AUTOSAR XML (schema 4-3-0)
package /ComponentTypes
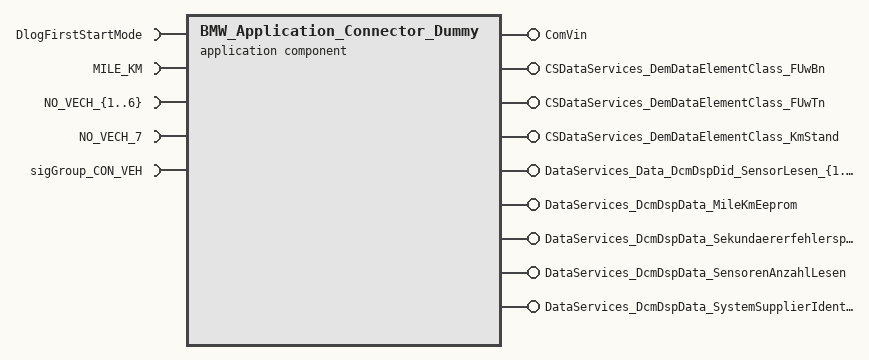
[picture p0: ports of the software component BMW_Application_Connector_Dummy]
  application sw component type BMW_Application_Connector_Dummy
    11 x provide port:
      ComVin: nonqueued-sender-com-spec{data-element=ComVin, init-value=fields=[Vin1:0, Vin2:0, Vin3:0, Vin4:0, Vin5:0, Vin6:0, Vin7:0]}, provided-interface=ComVin
      CSDataServices_DemDataElementClass_FUwBn: server-com-spec{operation=ReadData, queue-length=1}, provided-interface=CSDataServices_DemDataElementClass_FUwBn
      CSDataServices_DemDataElementClass_FUwTn: server-com-spec{operation=ReadData, queue-length=1}, provided-interface=CSDataServices_DemDataElementClass_FUwTn
      CSDataServices_DemDataElementClass_KmStand: server-com-spec{operation=ReadData, queue-length=1}, provided-interface=CSDataServices_DemDataElementClass_KmStand
      DataServices_Data_DcmDspDid_SensorLesen_{1..3}: provided-com-specs=[{operation=ConditionCheckRead, queue-length=1}, {operation=ReadData, queue-length=1}], provided-interface=DataServices_Data_DcmDspDid_SensorLesen_{1..3}
      DataServices_DcmDspData_MileKmEeprom: provided-com-specs=[{operation=ConditionCheckRead, queue-length=1}, {operation=ReadData, queue-length=1}], provided-interface=DataServices_DcmDspData_MileKmEeprom
      DataServices_DcmDspData_Sekundaererfehlerspeicher: provided-com-specs=[{operation=ConditionCheckRead, queue-length=1}, {operation=ReadData, queue-length=1}], provided-interface=DataServices_DcmDspData_Sekundaererfehlerspeicher
      DataServices_DcmDspData_SensorenAnzahlLesen: provided-com-specs=[{operation=ConditionCheckRead, queue-length=1}, {operation=ReadData, queue-length=1}], provided-interface=DataServices_DcmDspData_SensorenAnzahlLesen
      DataServices_DcmDspData_SystemSupplierIdentifier: provided-com-specs=[{operation=ConditionCheckRead, queue-length=1}, {operation=ReadData, queue-length=1}], provided-interface=DataServices_DcmDspData_SystemSupplierIdentifier
    10 x require port:
      DlogFirstStartMode: mode-switch-receiver-com-spec{enhanced-mode-api=false, supports-asynchronous-mode-switch=false}, required-interface=DlogFirstStartMode
      MILE_KM: nonqueued-receiver-com-spec{data-element=MILE_KM, filter=data-filter-type=ALWAYS, handle-never-received=true, init-value=0}, required-interface=MILE_KM
      NO_VECH_{1..6}: nonqueued-receiver-com-spec{data-element=NO_VECH_{1..6}, filter=data-filter-type=ALWAYS, init-value=constant-reference=NO_VECH_InitValue}, required-interface=NO_VECH_{1..6}
      NO_VECH_7: nonqueued-receiver-com-spec{data-element=NO_VECH_7, alive-timeout=3, filter=data-filter-type=ALWAYS, init-value=constant-reference=NO_VECH_InitValue}, required-interface=NO_VECH_7
      sigGroup_CON_VEH: nonqueued-receiver-com-spec{data-element=sigGroup_CON_VEH, filter=data-filter-type=ALWAYS, handle-never-received=true, init-value=fields=[ElementConstant:0, ElementConstant_1:0, ElementConstant_2:0, ElementConstant_3:0, ElementConstant_4:0, ElementConstant_5:0, ElementConstant_6:0]}, required-interface=sigGroup_CON_VEH
    behavior BMW_Application_Connector_Dummy_InternalBehavior
      data received event DRT_BMW_Vin_Rx_Wrapper_NO_VECH_7_NO_VECH_7: start-on-event=BMW_Vin_Rx_Wrapper, data=NO_VECH_7.NO_VECH_7
      data receive error event DRET_BMW_Vin_Rx_Wrapper_NO_VECH_7_NO_VECH_7: start-on-event=BMW_Vin_Rx_Wrapper, data=NO_VECH_7.NO_VECH_7
      17 x operation invoked event:
        OIT_CSDataServices_DemDataElementClass_FUwBn_ReadData_CSDataServices_DemDataElementClass_FUwBn_ReadData: start-on-event=CSDataServices_DemDataElementClass_FUwBn_ReadData, operation=CSDataServices_DemDataElementClass_FUwBn.ReadData
        OIT_CSDataServices_DemDataElementClass_FUwTn_ReadData_CSDataServices_DemDataElementClass_FUwTn_ReadData: start-on-event=CSDataServices_DemDataElementClass_FUwTn_ReadData, operation=CSDataServices_DemDataElementClass_FUwTn.ReadData
        OIT_CSDataServices_DemDataElementClass_KmStand_ReadData_CSDataServices_DemDataElementClass_KmStand_ReadData: start-on-event=CSDataServices_DemDataElementClass_KmStand_ReadData, operation=CSDataServices_DemDataElementClass_KmStand.ReadData
        OIT_DataServices_Data_DcmDspDid_SensorLesen_1_ConditionCheckRead_DataServices_Data_DcmDspDid_SensorLesen_1_ConditionCheckRead: start-on-event=DataServices_Data_DcmDspDid_SensorLesen_1_ConditionCheckRead, operation=DataServices_Data_DcmDspDid_SensorLesen_1.ConditionCheckRead
        OIT_DataServices_Data_DcmDspDid_SensorLesen_1_ReadData_DataServices_Data_DcmDspDid_SensorLesen_1_ReadData: start-on-event=DataServices_Data_DcmDspDid_SensorLesen_1_ReadData, operation=DataServices_Data_DcmDspDid_SensorLesen_1.ReadData
        OIT_DataServices_Data_DcmDspDid_SensorLesen_2_ConditionCheckRead_DataServices_Data_DcmDspDid_SensorLesen_2_ConditionCheckRead: start-on-event=DataServices_Data_DcmDspDid_SensorLesen_2_ConditionCheckRead, operation=DataServices_Data_DcmDspDid_SensorLesen_2.ConditionCheckRead
        OIT_DataServices_Data_DcmDspDid_SensorLesen_2_ReadData_DataServices_Data_DcmDspDid_SensorLesen_2_ReadData: start-on-event=DataServices_Data_DcmDspDid_SensorLesen_2_ReadData, operation=DataServices_Data_DcmDspDid_SensorLesen_2.ReadData
        OIT_DataServices_Data_DcmDspDid_SensorLesen_3_ConditionCheckRead_DataServices_Data_DcmDspDid_SensorLesen_3_ConditionCheckRead: start-on-event=DataServices_Data_DcmDspDid_SensorLesen_3_ConditionCheckRead, operation=DataServices_Data_DcmDspDid_SensorLesen_3.ConditionCheckRead
        OIT_DataServices_Data_DcmDspDid_SensorLesen_3_ReadData_DataServices_Data_DcmDspDid_SensorLesen_3_ReadData: start-on-event=DataServices_Data_DcmDspDid_SensorLesen_3_ReadData, operation=DataServices_Data_DcmDspDid_SensorLesen_3.ReadData
        OIT_DataServices_DcmDspData_MileKmEeprom_ConditionCheckRead_DataServices_DcmDspData_MileKmEeprom_ConditionCheckRead: start-on-event=DataServices_DcmDspData_MileKmEeprom_ConditionCheckRead, operation=DataServices_DcmDspData_MileKmEeprom.ConditionCheckRead
        OIT_DataServices_DcmDspData_MileKmEeprom_ReadData_DataServices_DcmDspData_MileKmEeprom_ReadData: start-on-event=DataServices_DcmDspData_MileKmEeprom_ReadData, operation=DataServices_DcmDspData_MileKmEeprom.ReadData
        OIT_DataServices_DcmDspData_Sekundaererfehlerspeicher_ConditionCheckRead_DataServices_DcmDspData_Sekundaererfehlerspeich292DEEC9: start-on-event=DataServices_DcmDspData_Sekundaererfehlerspeicher_ConditionCheckRead, operation=DataServices_DcmDspData_Sekundaererfehlerspeicher.ConditionCheckRead
        OIT_DataServices_DcmDspData_Sekundaererfehlerspeicher_ReadData_DataServices_DcmDspData_Sekundaererfehlerspeicher_ReadData: start-on-event=DataServices_DcmDspData_Sekundaererfehlerspeicher_ReadData, operation=DataServices_DcmDspData_Sekundaererfehlerspeicher.ReadData
        OIT_DataServices_DcmDspData_SensorenAnzahlLesen_ConditionCheckRead_DataServices_DcmDspData_SensorenAnzahlLesen_Condition055FF87D: start-on-event=DataServices_DcmDspData_SensorenAnzahlLesen_ConditionCheckRead, operation=DataServices_DcmDspData_SensorenAnzahlLesen.ConditionCheckRead
        OIT_DataServices_DcmDspData_SensorenAnzahlLesen_ReadData_DataServices_DcmDspData_SensorenAnzahlLesen_ReadData: start-on-event=DataServices_DcmDspData_SensorenAnzahlLesen_ReadData, operation=DataServices_DcmDspData_SensorenAnzahlLesen.ReadData
        OIT_DataServices_DcmDspData_SystemSupplierIdentifier_ConditionCheckRead_DataServices_DcmDspData_SystemSupplierIdentifier335977C2: start-on-event=DataServices_DcmDspData_SystemSupplierIdentifier_ConditionCheckRead, operation=DataServices_DcmDspData_SystemSupplierIdentifier.ConditionCheckRead
        OIT_DataServices_DcmDspData_SystemSupplierIdentifier_ReadData_DataServices_DcmDspData_SystemSupplierIdentifier_ReadData: start-on-event=DataServices_DcmDspData_SystemSupplierIdentifier_ReadData, operation=DataServices_DcmDspData_SystemSupplierIdentifier.ReadData
      swc mode switch event MST_Dlog_FirstStart_Dummy_1: start-on-event=Dlog_FirstStart_Dummy, activation=ON-ENTRY, mode=DlogFirstStartMode.DlogFirstStartMode.DLOG_NORMALSTART
      swc mode switch event MST_Dlog_FirstStart_Dummy_0: start-on-event=Dlog_FirstStart_Dummy, activation=ON-ENTRY, mode=DlogFirstStartMode.DlogFirstStartMode.DLOG_FIRSTSTART
      port-api-options:
        enable-take-address=false, error-handling=NO-TRANSFORMER-ERROR-HANDLING, indirect-api=false, port=DataServices_DcmDspData_MileKmEeprom
        enable-take-address=false, error-handling=NO-TRANSFORMER-ERROR-HANDLING, indirect-api=false, port=DataServices_DcmDspData_Sekundaererfehlerspeicher
        enable-take-address=false, error-handling=NO-TRANSFORMER-ERROR-HANDLING, indirect-api=false, port=DataServices_DcmDspData_SensorenAnzahlLesen
        enable-take-address=false, error-handling=NO-TRANSFORMER-ERROR-HANDLING, indirect-api=false, port=DataServices_DcmDspData_SystemSupplierIdentifier
        enable-take-address=false, error-handling=NO-TRANSFORMER-ERROR-HANDLING, indirect-api=false, port=DlogFirstStartMode
        enable-take-address=false, error-handling=NO-TRANSFORMER-ERROR-HANDLING, indirect-api=false, port=MILE_KM
        enable-take-address=false, error-handling=NO-TRANSFORMER-ERROR-HANDLING, indirect-api=false, port=NO_VECH_{1..7}
        enable-take-address=false, error-handling=NO-TRANSFORMER-ERROR-HANDLING, indirect-api=false, port=sigGroup_CON_VEH
      19 x runnable:
        BMW_Vin_Rx_Wrapper  # VIN is provided as PDU with single signals but VIN Module expects a signal group
          data-receive-point-by-arguments:
            7 x access:
              REC_NO_VECH_{1..7}_NO_VECH_{1..7}: accessed-variable=NO_VECH_{1..7}.NO_VECH_{1..7}
          data-send-points:
            access SEND_ComVin_ComVin: accessed-variable=ComVin.ComVin
        CSDataServices_DemDataElementClass_FUwBn_ReadData
          data-receive-point-by-arguments:
            access REC_sigGroup_CON_VEH_sigGroup_CON_VEH: accessed-variable=sigGroup_CON_VEH.sigGroup_CON_VEH
        CSDataServices_DemDataElementClass_FUwTn_ReadData
          data-receive-point-by-arguments:
            access REC_sigGroup_CON_VEH_sigGroup_CON_VEH: accessed-variable=sigGroup_CON_VEH.sigGroup_CON_VEH
        CSDataServices_DemDataElementClass_KmStand_ReadData
          data-receive-point-by-arguments:
            access REC_MILE_KM_MILE_KM: accessed-variable=MILE_KM.MILE_KM
        DataServices_Data_DcmDspDid_SensorLesen_1_ConditionCheckRead
        DataServices_Data_DcmDspDid_SensorLesen_1_ReadData
        DataServices_Data_DcmDspDid_SensorLesen_2_ConditionCheckRead
        DataServices_Data_DcmDspDid_SensorLesen_2_ReadData
        DataServices_Data_DcmDspDid_SensorLesen_3_ConditionCheckRead
        DataServices_Data_DcmDspDid_SensorLesen_3_ReadData
        DataServices_DcmDspData_MileKmEeprom_ConditionCheckRead
        DataServices_DcmDspData_MileKmEeprom_ReadData
          data-receive-point-by-arguments:
            access REC_MILE_KM_MILE_KM: accessed-variable=MILE_KM.MILE_KM
        DataServices_DcmDspData_Sekundaererfehlerspeicher_ConditionCheckRead
        DataServices_DcmDspData_Sekundaererfehlerspeicher_ReadData
        DataServices_DcmDspData_SensorenAnzahlLesen_ConditionCheckRead
        DataServices_DcmDspData_SensorenAnzahlLesen_ReadData
        DataServices_DcmDspData_SystemSupplierIdentifier_ConditionCheckRead
        DataServices_DcmDspData_SystemSupplierIdentifier_ReadData
        Dlog_FirstStart_Dummy: mode-access-point=DlogFirstStartMode.DlogFirstStartMode
  swc implementation BMW_Application_Connector_Dummy_Implementation: behavior=BMW_Application_Connector_Dummy_InternalBehavior
    code-descriptors:
      code Default: artifact-descriptors=autosar-engineering-object={short-label=Default, category=SWSRC}
